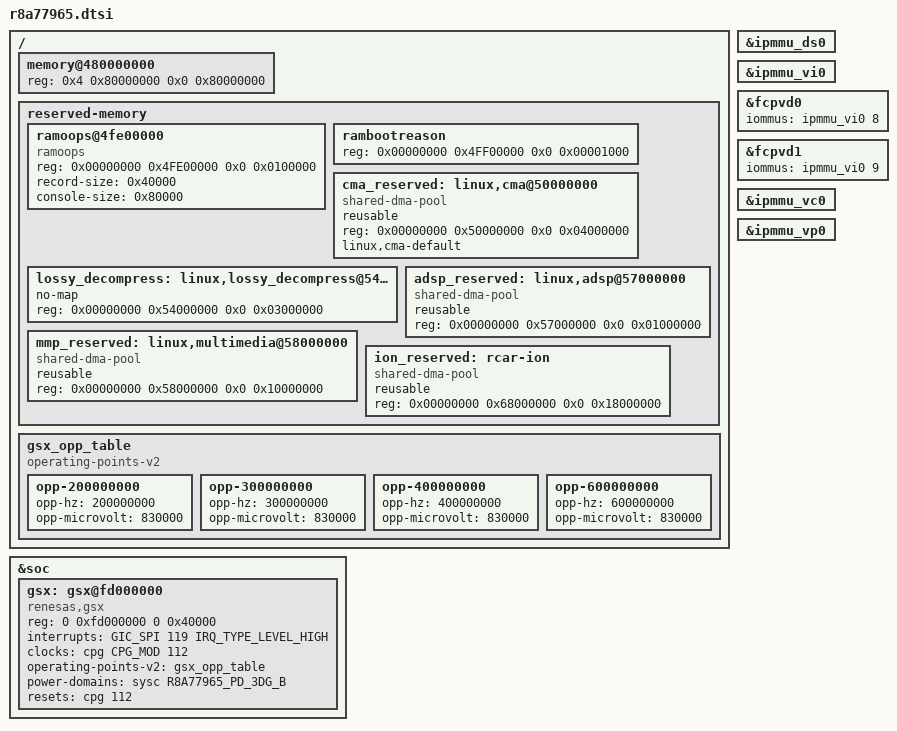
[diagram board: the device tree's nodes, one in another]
/*
 * Device Tree Source for the Android
 *
 * Copyright (C) 2018 GlobalLogic
 *
 * This file is licensed under the terms of the GNU General Public License
 * version 2.  This program is licensed "as is" without any warranty of any
 * kind, whether express or implied.
 */

#include "fstab.dtsi"
#include "common.dtsi"

/ {
	memory@480000000 {
		device_type = "memory";
		reg = <0x4 0x80000000 0x0 0x80000000>;
	};

	/delete-node/ reserved-memory;

	reserved-memory {
		#address-cells = <2>;
		#size-cells = <2>;
		ranges;

		ramoops@4fe00000 {
			compatible = "ramoops";
			reg = <0x00000000 0x4FE00000 0x0 0x0100000>; /* 1MB */
			record-size = <0x40000>;
			console-size = <0x80000>;
		};

		rambootreason {
			reg = <0x00000000 0x4FF00000 0x0 0x00001000>;
		};

		/* global autoconfigured region for contiguous allocations */
		cma_reserved: linux,cma@50000000 {
			compatible = "shared-dma-pool";
			reusable;
			reg = <0x00000000 0x50000000 0x0 0x04000000>; /* 64Mb */
			linux,cma-default;
		};

		/* device specific region for Lossy Decompression */
		lossy_decompress: linux,lossy_decompress@54000000 {
			no-map;
			reg = <0x00000000 0x54000000 0x0 0x03000000>;
		};

		adsp_reserved: linux,adsp@57000000 {
			compatible = "shared-dma-pool";
			reusable;
			reg = <0x00000000 0x57000000 0x0 0x01000000>;
		};

		/* device specific region for contiguous allocations */
		mmp_reserved: linux,multimedia@58000000 {
			compatible = "shared-dma-pool";
			reusable;
			reg = <0x00000000 0x58000000 0x0 0x10000000>; /* 256Mb */
		};

		ion_reserved: rcar-ion {
			compatible = "shared-dma-pool";
			reusable;
			reg = <0x00000000 0x68000000 0x0 0x18000000>; /* 384Mb */
		};
	};

	gsx_opp_table: gsx_opp_table {
		compatible = "operating-points-v2";

		opp-200000000 {
			opp-hz = /bits/ 64 <200000000>;
			opp-microvolt = <830000>;
		};
		opp-300000000 {
			opp-hz = /bits/ 64 <300000000>;
			opp-microvolt = <830000>;
		};
		opp-400000000 {
			opp-hz = /bits/ 64 <400000000>;
			opp-microvolt = <830000>;
		};
		opp-600000000 {
			opp-hz = /bits/ 64 <600000000>;
			opp-microvolt = <830000>;
		};
	};
};

&soc {
	gsx: gsx@fd000000 {
		compatible = "renesas,gsx";
		reg = <0 0xfd000000 0 0x40000>;
		interrupts = <GIC_SPI 119 IRQ_TYPE_LEVEL_HIGH>;
		clocks = <&cpg CPG_MOD 112>;
		operating-points-v2 = <&gsx_opp_table>;
		power-domains = <&sysc R8A77965_PD_3DG_B>;
		resets = <&cpg 112>;
	};
};

&ipmmu_ds0 {
	status = "okay";
};

&ipmmu_vi0 {
	status = "okay";
};

&fcpvd0 {
	iommus = <&ipmmu_vi0 8>;
};

&fcpvd1 {
	iommus = <&ipmmu_vi0 9>;
};

&ipmmu_vc0 {
	status = "okay";
};

&ipmmu_vp0 {
	status = "okay";
};
